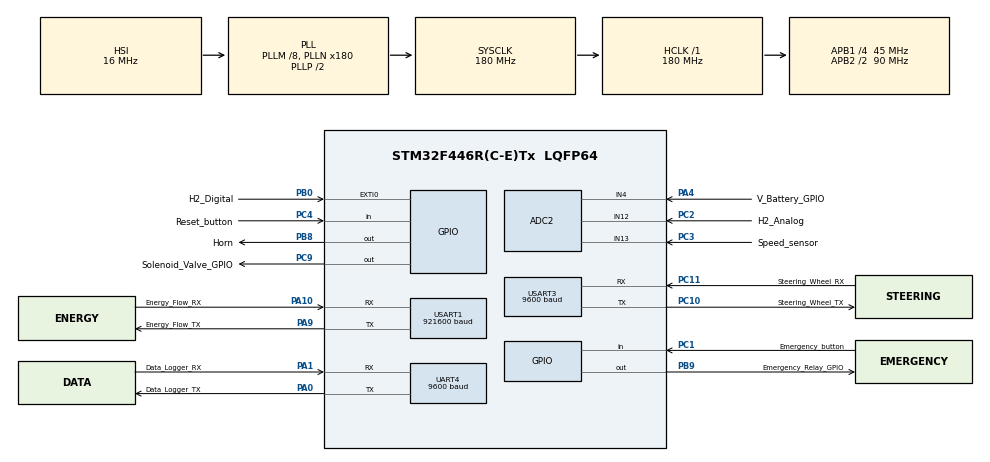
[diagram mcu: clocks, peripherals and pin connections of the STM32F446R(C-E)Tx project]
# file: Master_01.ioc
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Mcu.Family=STM32F4
NVIC.USART3_IRQn=true\:0\:0\:false\:false\:true\:true\:true
ADC2.ExternalTrigConv=ADC_EXTERNALTRIGCONV_T2_TRGO
Dma.UART4_RX.1.Mode=DMA_NORMAL
PH0-OSC_IN.Signal=RCC_OSC_IN
RCC.CortexFreq_Value=180000000
Dma.UART4_RX.1.MemDataAlignment=DMA_MDATAALIGN_BYTE
Dma.UART4_TX.2.Direction=DMA_MEMORY_TO_PERIPH
ADC2.Channel-0\#ChannelRegularConversion=ADC_CHANNEL_12
NVIC.TIM6_DAC_IRQn=true\:0\:0\:false\:false\:true\:true\:true
USART1.BaudRate=921600
NVIC.DMA1_Stream2_IRQn=true\:0\:0\:false\:false\:true\:false\:true
PC10.Signal=USART3_TX
VP_IWDG_VS_IWDG.Mode=IWDG_Activate
PA14.GPIO_Label=TCK
PB0.GPIO_Label=H2_Digital
NVIC.DMA1_Stream4_IRQn=true\:0\:0\:false\:false\:true\:false\:true
Dma.USART3_RX.3.Mode=DMA_NORMAL
RCC.SYSCLKSource=RCC_SYSCLKSOURCE_PLLCLK
ProjectManager.StackSize=0x400
Dma.USART3_RX.3.MemDataAlignment=DMA_MDATAALIGN_BYTE
VP_TIM7_VS_ClockSourceINT.Mode=Enable_Timer
NVIC.ADC_IRQn=true\:0\:0\:false\:false\:true\:true\:true
USART3.BaudRate=9600
ADC2.DMAContinuousRequests=ENABLE
Dma.USART3_RX.3.PeriphDataAlignment=DMA_PDATAALIGN_BYTE
UART4.BaudRate=9600
RCC.HCLKFreq_Value=180000000
Dma.USART1_RX.4.MemDataAlignment=DMA_MDATAALIGN_BYTE
Dma.ADC2.0.Direction=DMA_PERIPH_TO_MEMORY
RCC.APB2TimFreq_Value=180000000
Dma.ADC2.0.MemInc=DMA_MINC_ENABLE
PC3.Signal=ADCx_IN13
TIM7.Period=1000-1
Dma.UART4_RX.1.FIFOMode=DMA_FIFOMODE_DISABLE
ADC2.EOCSelection=ADC_EOC_SINGLE_CONV
RCC.AHBFreq_Value=180000000
PH0-OSC_IN.Mode=HSE-External-Oscillator
Dma.ADC2.0.Priority=DMA_PRIORITY_LOW
RCC.HSE_VALUE=8000000
Dma.UART4_RX.1.MemInc=DMA_MINC_ENABLE
Dma.USART3_RX.3.Instance=DMA1_Stream1
PB0.GPIO_ModeDefaultEXTI=GPIO_MODE_IT_FALLING
Dma.UART4_TX.2.Instance=DMA1_Stream4
Dma.USART1_RX.4.Instance=DMA2_Stream5
PC14-OSC32_IN.Mode=LSE-External-Oscillator
PC4.GPIO_Label=Reset_button
PC11.GPIO_Label=Steering_Wheel_RX
NVIC.TIM2_IRQn=true\:0\:0\:false\:false\:true\:true\:true
PA10.GPIO_Label=Energy_Flow_RX
Dma.USART3_RX.3.PeriphInc=DMA_PINC_DISABLE
TIM6.Period=100-1
RCC.FLatency-AdvancedSettings=FLASH_LATENCY_5
Dma.UART4_TX.2.MemDataAlignment=DMA_MDATAALIGN_BYTE
Dma.UART4_TX.2.PeriphInc=DMA_PINC_DISABLE
PH1-OSC_OUT.Mode=HSE-External-Oscillator
PB9.Signal=GPIO_Output
Mcu.Package=LQFP64
TIM2.Prescaler=8399
Dma.USART1_RX.4.Direction=DMA_PERIPH_TO_MEMORY
Dma.UART4_RX.1.PeriphDataAlignment=DMA_PDATAALIGN_BYTE
PA10.Signal=USART1_RX
ADC2.SamplingTime-0\#ChannelRegularConversion=ADC_SAMPLETIME_480CYCLES
TIM7.AutoReloadPreload=TIM_AUTORELOAD_PRELOAD_ENABLE
PC11.Mode=Asynchronous
Dma.ADC2.0.Mode=DMA_CIRCULAR
Dma.USART3_RX.3.MemInc=DMA_MINC_ENABLE
Dma.UART4_TX.2.FIFOMode=DMA_FIFOMODE_DISABLE
TIM2.TIM_MasterOutputTrigger=TIM_TRGO_UPDATE
RCC.APB2CLKDivider=RCC_HCLK_DIV2
Dma.ADC2.0.PeriphDataAlignment=DMA_PDATAALIGN_HALFWORD
NVIC.DMA2_Stream2_IRQn=true\:0\:0\:false\:false\:true\:false\:true
ADC2.NbrOfConversion=1
Dma.Request2=UART4_TX
Dma.Request1=UART4_RX
RCC.APB1TimFreq_Value=90000000
Dma.Request4=USART1_RX
Dma.Request3=USART3_RX
ADC2.Rank-0\#ChannelRegularConversion=1
NVIC.USART1_IRQn=true\:0\:0\:false\:false\:true\:true\:true
Dma.Request0=ADC2
UART4.OverSampling=UART_OVERSAMPLING_8
PA4.GPIO_Label=V_Battery_GPIO
PC2.GPIO_Label=H2_Analog
Dma.UART4_TX.2.Mode=DMA_NORMAL
NVIC.TIM7_IRQn=true\:0\:0\:false\:false\:true\:true\:true
Dma.UART4_RX.1.Direction=DMA_PERIPH_TO_MEMORY
ADC2.ScanConvMode=ENABLE
NVIC.UART4_IRQn=true\:0\:0\:false\:false\:true\:true\:true
PB3.GPIO_Label=SWO
ADC2.ClockPrescaler=ADC_CLOCK_SYNC_PCLK_DIV8
PC15-OSC32_OUT.Mode=LSE-External-Oscillator
Dma.USART3_RX.3.Direction=DMA_PERIPH_TO_MEMORY
SH.ADCx_IN13.0=ADC2_IN13,IN13
PB9.GPIO_Label=Emergency_Relay_GPIO
PA10.Mode=Asynchronous
PC10.GPIO_Label=Steering_Wheel_TX
PC9.GPIO_Label=Solenoid_Valve_GPIO
PA9.GPIO_Label=Energy_Flow_TX
PC11.Signal=USART3_RX
TIM6.Prescaler=90-1
PC2.Signal=ADCx_IN12
PC4.Signal=GPIO_Input
PC10.Mode=Asynchronous
VP_TIM6_VS_ClockSourceINT.Mode=Enable_Timer
Dma.USART1_RX.4.Priority=DMA_PRIORITY_LOW
Dma.UART4_TX.2.PeriphDataAlignment=DMA_PDATAALIGN_BYTE
Dma.UART4_TX.2.Priority=DMA_PRIORITY_LOW
NVIC.DMA1_Stream1_IRQn=true\:0\:0\:false\:false\:true\:false\:true
Dma.USART1_RX.4.Mode=DMA_NORMAL
RCC.APB1CLKDivider=RCC_HCLK_DIV4
UART4.VirtualMode=Asynchronous
PC14-OSC32_IN.Signal=RCC_OSC32_IN
Dma.USART1_RX.4.FIFOMode=DMA_FIFOMODE_DISABLE
PA0-WKUP.GPIO_Label=Data_Logger_TX
PA0-WKUP.Signal=UART4_TX
PA0-WKUP.Mode=Asynchronous
PA13.Signal=SYS_JTMS-SWDIO
PB8.GPIO_Label=Horn
PA9.Mode=Asynchronous
SH.ADCx_IN12.0=ADC2_IN12,IN12
Dma.UART4_TX.2.MemInc=DMA_MINC_ENABLE
ADC2.ContinuousConvMode=ENABLE
ProjectManager.TargetToolchain=STM32CubeIDE
Dma.UART4_RX.1.Instance=DMA1_Stream2
Dma.ADC2.0.MemDataAlignment=DMA_MDATAALIGN_HALFWORD
Dma.USART3_RX.3.FIFOMode=DMA_FIFOMODE_DISABLE
PA9.Signal=USART1_TX
RCC.USBFreq_Value=180000000
PC15-OSC32_OUT.Signal=RCC_OSC32_OUT
PA1.Signal=UART4_RX
TIM7.Prescaler=90-1
board=NUCLEO-F446RE
RCC.VCOOutputFreq_Value=360000000
Dma.ADC2.0.PeriphInc=DMA_PINC_DISABLE
RCC.APB2Freq_Value=90000000
PA1.Mode=Asynchronous
VP_TIM2_VS_ClockSourceINT.Mode=Internal
Dma.USART1_RX.4.PeriphDataAlignment=DMA_PDATAALIGN_BYTE
NVIC.DMA2_Stream5_IRQn=true\:0\:0\:false\:false\:true\:false\:true
PA1.GPIO_Label=Data_Logger_RX
PC1.GPIO_Label=Emergency_button
PH1-OSC_OUT.Signal=RCC_OSC_OUT
SH.ADCx_IN4.0=ADC2_IN4,IN4
TIM2.Period=49
Mcu.Name=STM32F446R(C-E)Tx
PA13.GPIO_Label=TMS
RCC.48MHZClocksFreq_Value=84000000
PB3.Signal=SYS_JTDO-SWO
NVIC.EXTI0_IRQn=true\:0\:0\:false\:false\:true\:true\:true
PA4.Signal=ADCx_IN4
RCC.SYSCLKFreq_VALUE=180000000
USART1.OverSampling=UART_OVERSAMPLING_8
ADC2.NbrOfConversionFlag=1
USART3.VirtualMode=VM_ASYNC
USART1.VirtualMode=VM_ASYNC
PA14.Signal=SYS_JTCK-SWCLK
Dma.USART1_RX.4.MemInc=DMA_MINC_ENABLE
ProjectManager.HeapSize=0x200
Dma.UART4_RX.1.PeriphInc=DMA_PINC_DISABLE
Dma.ADC2.0.FIFOMode=DMA_FIFOMODE_DISABLE
RCC.HSI_VALUE=16000000
ADC2.ExternalTrigConvEdge=ADC_EXTERNALTRIGCONVEDGE_RISING
NVIC.PriorityGroup=NVIC_PRIORITYGROUP_0
Dma.UART4_RX.1.Priority=DMA_PRIORITY_LOW
RCC.PLLM=8
RCC.PLLN=180
PB8.Signal=GPIO_Output
PC3.GPIO_Label=Speed_sensor
Dma.USART3_RX.3.Priority=DMA_PRIORITY_LOW
Dma.USART1_RX.4.PeriphInc=DMA_PINC_DISABLE
PC9.Signal=GPIO_Output
RCC.APB1Freq_Value=45000000
VP_CRC_VS_CRC.Mode=CRC_Activate
Dma.ADC2.0.Instance=DMA2_Stream2
PB0.Signal=GPXTI0
PC1.Signal=GPIO_Input
PB0.GPIO_PuPd=GPIO_PULLUP

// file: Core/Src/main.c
/* USER CODE BEGIN Header */
/**
  ******************************************************************************
  * @file           : main.c
  * @brief          : Main program body
  ******************************************************************************
  * @attention
  *
  * <h2><center>&copy; Copyright (c) 2021 STMicroelectronics.
  * All rights reserved.</center></h2>
  *
  * This software component is licensed by ST under BSD 3-Clause license,
  * the "License"; You may not use this file except in compliance with the
  * License. You may obtain a copy of the License at:
  *                        opensource.org/licenses/BSD-3-Clause
  *
  ******************************************************************************
  */
/* USER CODE END Header */
#include "main.h"
#include "adc.h"
#include "crc.h"
#include "dma.h"
#include "iwdg.h"
#include "tim.h"
#include "usart.h"
#include "gpio.h"

/* USER CODE BEGIN Includes */
//#include <stdbool.h>
//#include <stdio.h>
#include "hydrogreen.h"
/* USER CODE END Includes */

/* USER CODE BEGIN PV */
/*
uint32_t adc_data;
uint8_t emergency_scenario_flag=0,Speed_Sensor_flag=0,speed_flag=0,no_send_flag=1;
int16_t size=3;
int i=0;
float v_time=0;
float velocity=0;
char data[3],Data[5];
uint16_t time=0,wait =0;
uint8_t a=0,b=0;
*/

/* USER CODE END PV */

void SystemClock_Config(void);
/* USER CODE BEGIN PFP */
//void HAL_SYSTICK_Callback();
//void ADC_SetActiveChannel(ADC_HandleTypeDef *hadc, uint32_t AdcChannel);
//void HAL_GPIO_EXTI_Callback(uint16_t GPIO_Pin);
/* USER CODE END PFP */

int main(void)
{

  /* MCU Configuration--------------------------------------------------------*/

  /* Reset of all peripherals, Initializes the Flash interface and the Systick. */
  HAL_Init();

  /* Configure the system clock */
  SystemClock_Config();

  /* Initialize all configured peripherals */
  MX_GPIO_Init();
  MX_DMA_Init();
  MX_UART4_Init();
  MX_USART1_UART_Init();
  MX_TIM2_Init();
  MX_ADC2_Init();
  MX_USART3_UART_Init();
  MX_CRC_Init();
  MX_IWDG_Init();
  MX_TIM6_Init();
  MX_TIM7_Init();
  /* USER CODE BEGIN 2 */
 // HAL_TIM_Base_Start_IT(&htim2);
  //HAL_ADC_Start_DMA(&hadc2, &adc_data, 1);
  hydrogreen_main();
  //ADC_SetActiveChannel( &hadc2,12);
  /* USER CODE END 2 */

  /* Infinite loop */
  while (1)
  {

    /* USER CODE BEGIN 3 */
	/*
	  if(wait>=5000 && !emergency_scenario_flag)
	  {
		  HAL_GPIO_WritePin(Valve_GPIO_Port, Valve_Pin, GPIO_PIN_SET);
		  HAL_GPIO_WritePin(Horn_GPIO_Port, Horn_Pin, GPIO_PIN_SET);
	  }
	  if(b>=9)
	  {
		  b=1;
	  }
	  if(emergency_scenario_flag&&no_send_flag)
	  {
	  	HAL_GPIO_WritePin(Valve_GPIO_Port, Valve_Pin, GPIO_PIN_RESET);
	  	HAL_GPIO_WritePin(Horn_GPIO_Port, Horn_Pin, GPIO_PIN_RESET);
	  	HAL_GPIO_WritePin(LD2_GPIO_Port, LD2_Pin, GPIO_PIN_SET);
	  	data[0]='E';
	  	data[1]='E';
	  	data[2]='E';
	  //	sprintf(Data, "%s\n\r",data );
	  	HAL_UART_Transmit_IT(&huart1, data, 3);
	  	no_send_flag=0;
	  }
	  if(time>=2000)
	  {
	  if(!emergency_scenario_flag)
	  {
		  switch(a)
		  {
		  case 0:
	  	data[0]='A';
	  	data[1]= b+48;
	  	data[2]=5+48;
	  	//sprintf(Data, "%s\n\r",data );
	  	HAL_UART_Transmit_IT(&huart1, data, 3);
	  	//HAL_GPIO_WritePin(Valve_GPIO_Port, Valve_Pin, GPIO_PIN_SET);
	  	a++;
	  	b++;
	  	break;
		  case 1:
			  	data[0]='B';
			  	data[1]= b+48;
			  	data[2]=5+48;
	 	//sprintf(Data, "%s\n\r",data );
	 	HAL_UART_Transmit_IT(&huart1, data, 3);
	  	//HAL_GPIO_WritePin(Valve_GPIO_Port, Valve_Pin, GPIO_PIN_SET);
	  	a++;
	  	b++;
	  	break;
		  case 2:
			  	data[0]='C';
			  	data[1]= b+48;
			  	data[2]=5+48;
	  //	sprintf(Data, "%s\n\r",data );
	  	HAL_UART_Transmit_IT(&huart1, data, 3);
	  	a=0;
	  	b++;
	  	break;
		  default:
			  break;
		  }
	  }
	  time=0;
	  }
	  HAL_Delay(255);
	  */
  }

  /* USER CODE END 3 */
}

void SystemClock_Config(void)
{
  RCC_OscInitTypeDef RCC_OscInitStruct = {0};
  RCC_ClkInitTypeDef RCC_ClkInitStruct = {0};

  /** Configure the main internal regulator output voltage
  */
  __HAL_RCC_PWR_CLK_ENABLE();
  __HAL_PWR_VOLTAGESCALING_CONFIG(PWR_REGULATOR_VOLTAGE_SCALE1);
  /** Initializes the RCC Oscillators according to the specified parameters
  * in the RCC_OscInitTypeDef structure.
  */
  RCC_OscInitStruct.OscillatorType = RCC_OSCILLATORTYPE_HSI|RCC_OSCILLATORTYPE_LSI;
  RCC_OscInitStruct.HSIState = RCC_HSI_ON;
  RCC_OscInitStruct.HSICalibrationValue = RCC_HSICALIBRATION_DEFAULT;
  RCC_OscInitStruct.LSIState = RCC_LSI_ON;
  RCC_OscInitStruct.PLL.PLLState = RCC_PLL_ON;
  RCC_OscInitStruct.PLL.PLLSource = RCC_PLLSOURCE_HSI;
  RCC_OscInitStruct.PLL.PLLM = 8;
  RCC_OscInitStruct.PLL.PLLN = 180;
  RCC_OscInitStruct.PLL.PLLP = RCC_PLLP_DIV2;
  RCC_OscInitStruct.PLL.PLLQ = 2;
  RCC_OscInitStruct.PLL.PLLR = 2;
  if (HAL_RCC_OscConfig(&RCC_OscInitStruct) != HAL_OK)
  {
    Error_Handler();
  }
  /** Activate the Over-Drive mode
  */
  if (HAL_PWREx_EnableOverDrive() != HAL_OK)
  {
    Error_Handler();
  }
  /** Initializes the CPU, AHB and APB buses clocks
  */
  RCC_ClkInitStruct.ClockType = RCC_CLOCKTYPE_HCLK|RCC_CLOCKTYPE_SYSCLK
                              |RCC_CLOCKTYPE_PCLK1|RCC_CLOCKTYPE_PCLK2;
  RCC_ClkInitStruct.SYSCLKSource = RCC_SYSCLKSOURCE_PLLCLK;
  RCC_ClkInitStruct.AHBCLKDivider = RCC_SYSCLK_DIV1;
  RCC_ClkInitStruct.APB1CLKDivider = RCC_HCLK_DIV4;
  RCC_ClkInitStruct.APB2CLKDivider = RCC_HCLK_DIV2;

  if (HAL_RCC_ClockConfig(&RCC_ClkInitStruct, FLASH_LATENCY_5) != HAL_OK)
  {
    Error_Handler();
  }
}

/* USER CODE BEGIN 4 */
/*
void HAL_SYSTICK_Callback()
{
	if(wait<=5000)
	{
	wait++;
	}
	time++;
i++;
if(Speed_Sensor_flag)
{
	v_time=i;
	i=0;
	velocity=(1/v_time)*1000;
	Speed_Sensor_flag=0;
}
if(i>=200)
{
	velocity=0;
}
}

 void ADC_SetActiveChannel(ADC_HandleTypeDef *hadc, uint32_t AdcChannel)
{
  ADC_ChannelConfTypeDef sConfig = {0};
  sConfig.Channel = AdcChannel;
  sConfig.Rank = 1;
  sConfig.SamplingTime = ADC_SAMPLETIME_3CYCLES;
  if (HAL_ADC_ConfigChannel(hadc, &sConfig) != HAL_OK)
  {
   Error_Handler();
  }
}

void HAL_GPIO_EXTI_Callback(uint16_t GPIO_Pin){
	switch( GPIO_Pin)
	{
	case H2_Digital_Pin:
		emergency_scenario_flag=1;
		break;
	case Emergency_button_Pin:
		emergency_scenario_flag=1;
		break;
	case Speed_sensor_Pin:
		Speed_Sensor_flag=1;
		break;
	default:
		break;
	}
}

*/
/* USER CODE END 4 */

void Error_Handler(void)
{
  /* USER CODE BEGIN Error_Handler_Debug */
	hydrogreen_hardFault();
  /* User can add his own implementation to report the HAL error return state */

  /* USER CODE END Error_Handler_Debug */
}

/************************ (C) COPYRIGHT STMicroelectronics *****END OF FILE****/
